# CH32H41X register map
Vendor: WCH Ltd.; File version: 1.2
Registers are 32-bit, read-write, reset 0x0 unless marked. A register's access mark holds for its fields unless they carry their own. Offsets are from the block's base; [hi:lo] are bit positions; lines under a group give offsets from that group; {n}, {i} and the like mark numbered series.

## I3C — Improved inter-integrated circuit
Base 0x40014400
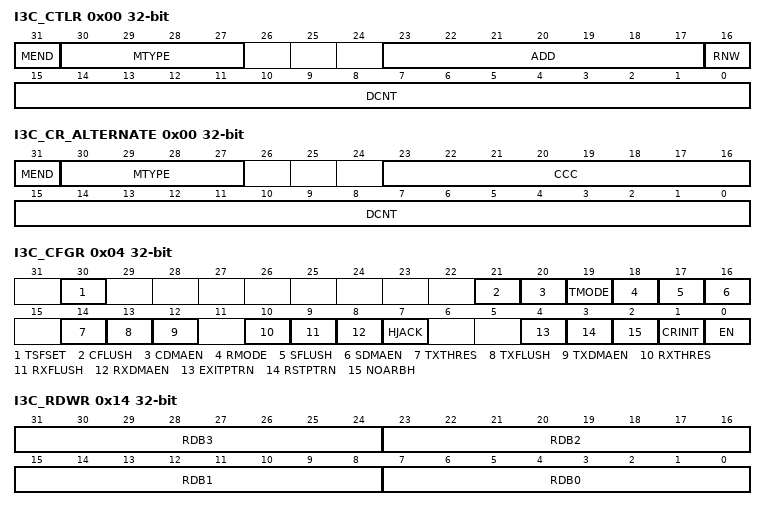
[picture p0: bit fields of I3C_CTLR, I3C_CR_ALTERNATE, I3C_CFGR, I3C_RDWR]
0x00 I3C_CTLR wo — I3C control register
  [31] MEND — message end type (when the I3C is acting as master)
  [30:27] MTYPE — message type
  [23:17] ADD — 7-bit I3C dynamic / I2C static slave address (when I3C is acting as master)
  [16] RNW — read / non-write message (when I3C is acting as master)
  [15:0] DCNT — count of data to transfer during a read or write message, in bytes (whatever I3C is acting as master/slave) Linear encoding up to 64 Kbytes -1
0x00 I3C_CR_ALTERNATE wo (alternate view of I3C_CTLR) — I3C message control register alternate
  [31] MEND — message end type (when I3C is acting as master)
  [30:27] MTYPE — message type (when I3C is acting as master)
  [23:16] CCC — 8-bit CCC code (when I3C is acting as master)
  [15:0] DCNT — count of data to transfer during a read or write message, in bytes (when I3C is acting as master) Linear encoding up to 64 Kbytes -1....
0x04 I3C_CFGR access per field — I3C configuration register
  [30] TSFSET wo — frame transfer set (a.k.a. software trigger) (when I3C is acting as master)
  [21] CFLUSH wo — C-FIFO flush (when I3C is acting as master)
  [20] CDMAEN rw — C-FIFO DMA request enable (when I3C is acting as master)
    0=DMA mode is disabled for C-FIFO; 1=DMA mode is enabled for C-FIFO
  [19] TMODE rw — transmit mode (when I3C is acting as master)
  [18] RMODE rw — S-FIFO enable / status receive mode (when I3C is acting as master)
  [17] SFLUSH wo — S-FIFO flush (when I3C is acting as master)
  [16] SDMAEN rw — S-FIFO DMA request enable (when I3C is acting as master)
  [14] TXTHRES rw — TX-FIFO threshold (whatever I3C is acting as master/slave)
  [13] TXFLUSH wo — TX-FIFO flush (whatever I3C is acting as master/slave)
  [12] TXDMAEN rw — TX-FIFO DMA request enable (whatever I3C is acting as master/slave)
  [10] RXTHRES rw — RX-FIFO threshold (whatever I3C is acting as master/slave)
  [9] RXFLUSH wo — RX-FIFO flush (whatever I3C is acting as master/slave)This bit can only be written.
  [8] RXDMAEN rw — RX-FIFO DMA request enable (whatever I3C is acting as master/slave)
  [7] HJACK rw — Hot Join request acknowledge (when I3C is acting as a master)
  [4] EXITPTRN rw — HDR Exit Pattern enable (when I3C is acting as a master)
  [3] RSTPTRN rw — HDR reset pattern enable (when I3C is acting as a master)
  [2] NOARBH rw — no arbitrable header after a START (when I3C is acting as a master)
  [1] CRINIT rw — initial master/slave role
  [0] EN rw — I3C enable (whatever I3C is acting as master/slave)
0x10 I3C_RDR ro — I3C receive data byte register
  [7:0] RDB0 — 8-bit received data on I3C bus.
0x14 I3C_RDWR ro — I3C receive data word register
  [31:24] RDB3 — 8-bit received data (latest byte on I3C bus).
  [23:16] RDB2 — 8-bit received data (next byte after RDB1 on I3C bus).
  [15:8] RDB1 — 8-bit received data (next byte after RDB0 on I3C bus).
  [7:0] RDB0 — 8-bit received data (earliest byte on I3C bus).
0x18 I3C_TDR wo — I3C transmit data byte register
  [7:0] TDB0 — 8-bit data to transmit on I3C bus.
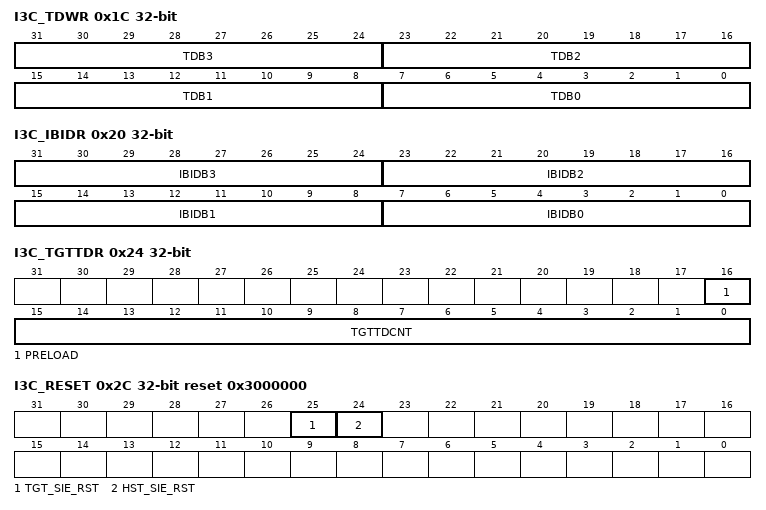
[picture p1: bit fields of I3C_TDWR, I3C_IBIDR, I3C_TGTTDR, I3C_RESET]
0x1C I3C_TDWR wo — I3C transmit data word register
  [31:24] TDB3 — 8-bit transmit data (latest byte on I3C bus).
  [23:16] TDB2 — 8-bit transmit data (next byte after TDB1[7:0] on I3C bus).
  [15:8] TDB1 — 8-bit transmit data (next byte after TDB0[7:0] on I3C bus).
  [7:0] TDB0 — 8-bit transmit data (earliest byte on I3C bus)
0x20 I3C_IBIDR — I3C IBI payload data register
  [31:24] IBIDB3 — 8-bit IBI payload data (latest byte on I3C bus).
  [23:16] IBIDB2 — 8-bit IBI payload data (next byte on I3C bus after IBIDB1[7:0]).
  [15:8] IBIDB1 — 8-bit IBI payload data (next byte on I3C bus after IBIDB0[7:0]).
  [7:0] IBIDB0 — 8-bit IBI payload data (earliest byte on I3C bus, i.e. MDB[7:0] mandatory data byte).
0x24 I3C_TGTTDR — I3C slave transmit configuration register
  [16] PRELOAD — preload of the TX-FIFO (when I3C is configured as slave)
  [15:0] TGTTDCNT — transmit data counter, in bytes (when I3C is configured as slave)
0x2C I3C_RESET reset 0x3000000
  [25] TGT_SIE_RST — Reset Register of the slave
  [24] HST_SIE_RST — Reset Register of the Master
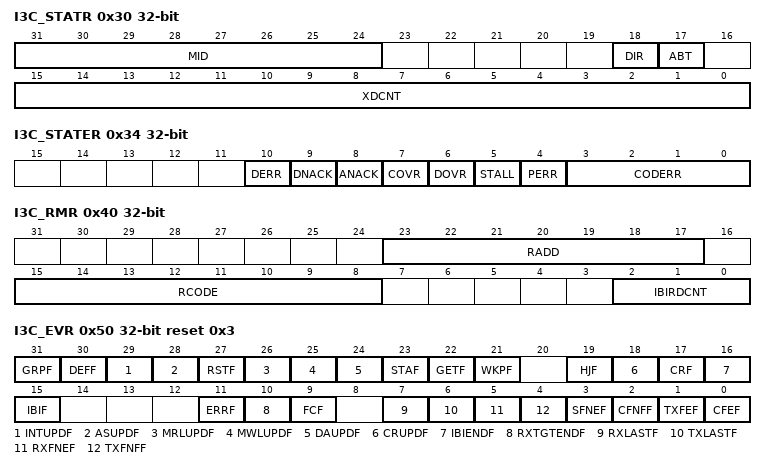
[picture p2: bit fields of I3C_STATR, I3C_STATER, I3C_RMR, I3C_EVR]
0x30 I3C_STATR ro — I3C status register
  [31:24] MID — message identifier/counter of a given frame (when the I3C is acting as master)
  [18] DIR — message direction(whatever I3C is acting as master/slave)
  [17] ABT — a private read message is completed/aborted prematurely by the slave (when the I3C is acting as master)
  [15:0] XDCNT — data counter
0x34 I3C_STATER ro — I3C status error register
  [10] DERR — data error (when the I3C is acting as master)
  [9] DNACK — data not acknowledged (when the I3C is acting as master)
  [8] ANACK — address not acknowledged (when the I3C is configured as master)
  [7] COVR — C-FIFO underrun or S-FIFO overrun (when the I3C is acting as master)
  [6] DOVR — RX-FIFO overrun or TX-FIFO underrun
  [5] STALL — SCL stall error (when the I3C is acting as slave)
  [4] PERR — protocol error
  [3:0] CODERR — protocol error code/type
0x40 I3C_RMR ro — I3C received message register
  [23:17] RADD — received slave address (when the I3C is configured as master)
  [15:8] RCODE — received CCC code (when the I3C is configured as slave)
  [2:0] IBIRDCNT — IBI received payload data count (when the I3C is configured as master)
0x50 I3C_EVR ro reset 0x3 — I3C event register
  [31] GRPF — group addressing flag (when the I3C is acting as slave)
  [30] DEFF — DEFTGTS flag (when the I3C is acting as slave)
  [29] INTUPDF — interrupt/master-role/hot-join update flag (when the I3C is acting as slave)
  [28] ASUPDF — activity state update flag (when the I3C is acting as slave)
  [27] RSTF — reset pattern flag (when the I3C is acting as slave)
  [26] MRLUPDF — maximum read length update flag (when the I3C is acting as slave)
  [25] MWLUPDF — maximum write length update flag (when the I3C is acting as slave)
  [24] DAUPDF — dynamic address update flag (when the I3C is acting as slave)
  [23] STAF — get status flag (when the I3C is acting as slave)
  [22] GETF — get flag (when the I3C is acting as slave)
  [21] WKPF — wakeup/missed start flag (when the I3C is acting as slave)
  [19] HJF — hot-join flag (when the I3C is acting as master)
  [18] CRUPDF — master-role update flag (when the I3C is acting as slave)
  [17] CRF — master-role request flag (when the I3C is acting as master)
  [16] IBIENDF — IBI end flag (when the I3C is acting as slave)
  [15] IBIF — IBI flag (when the I3C is acting as master)
  [11] ERRF — flag (whatever the I3C is acting as master/slave)
  [10] RXTGTENDF — slave-initiated read end flag (when the I3C is acting as master)
  [9] FCF — frame complete flag (whatever the I3C is acting as master/slave)
  [7] RXLASTF — last read data byte/word flag (whatever the I3C is acting as master/slave)
  [6] TXLASTF — last written data byte/word flag (whatever the I3C is acting as master/slave)
  [5] RXFNEF — RX-FIFO not empty flag (whatever the I3C is acting as master/slave)
  [4] TXFNFF — TX-FIFO not full flag (whatever the I3C is acting as master/slave)
  [3] SFNEF — S-FIFO not empty flag (when the I3C is acting as master)
  [2] CFNFF — C-FIFO not full flag (when the I3C is acting as master)
  [1] TXFEF — TX-FIFO empty flag (whatever the I3C is acting as master/slave)
  [0] CFEF — C-FIFO empty flag (whatever the I3C is acting as master/slave)
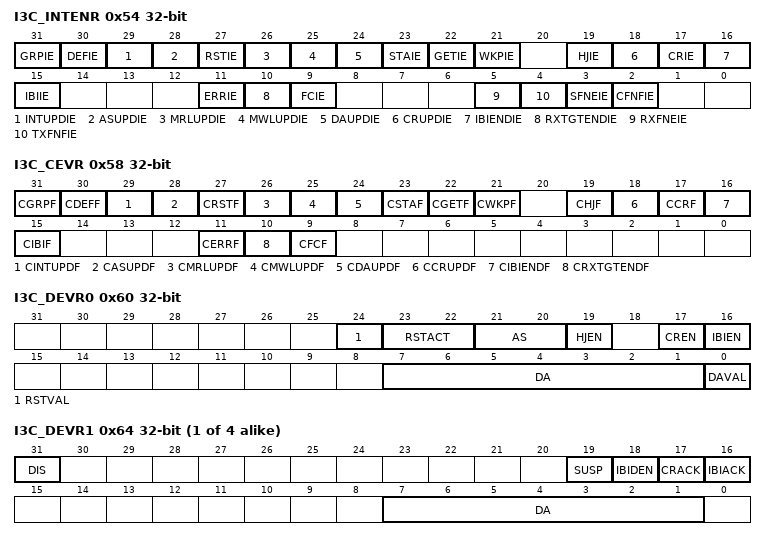
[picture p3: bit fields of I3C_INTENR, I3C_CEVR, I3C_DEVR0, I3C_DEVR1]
0x54 I3C_INTENR ro — I3C interrupt enable register
  [31] GRPIE — DEFGRPA CCC interrupt enable (when the I3C is acting as slave)
  [30] DEFIE — DEFTGTS CCC interrupt enable (when the I3C is acting as slave)
  [29] INTUPDIE — ENEC/DISEC CCC interrupt enable (when the I3C is acting as slave)
  [28] ASUPDIE — ENTASx CCC interrupt enable (when the I3C is acting as slave)
  [27] RSTIE — reset pattern interrupt enable (when the I3C is acting as slave)
  [26] MRLUPDIE — SETMRL CCC interrupt enable (when the I3C is acting as slave)
  [25] MWLUPDIE — SETMWL CCC interrupt enable (when the I3C is acting as slave)
  [24] DAUPDIE — ENTDAA/RSTDAA/SETNEWDA CCC interrupt enable (when the I3C is acting as slave)
  [23] STAIE — GETSTATUS CCC interrupt enable (when the I3C is acting as slave)
  [22] GETIE — GETxxx CCC interrupt enable (when the I3C is acting as slave)
  [21] WKPIE — wakeup interrupt enable (when the I3C is acting as slave)
  [19] HJIE — hot-join interrupt enable (when the I3C is acting as master)
  [18] CRUPDIE — master-role update interrupt enable (when the I3C is acting as slave)
  [17] CRIE — master-role request interrupt enable (when the I3C is acting as master)
  [16] IBIENDIE — IBI end interrupt enable (when the I3C is acting as slave)
  [15] IBIIE — IBI request interrupt enable (when the I3C is acting as master)
  [11] ERRIE — error interrupt enable (whatever the I3C is acting as master/slave)
  [10] RXTGTENDIE — slave-initiated read end interrupt enable (when the I3C is acting as master)
  [9] FCIE — frame complete interrupt enable (whatever the I3C is acting as master/slave)
  [5] RXFNEIE — RX-FIFO not empty interrupt enable (whatever the I3C is acting as master/slave)
  [4] TXFNFIE — TX-FIFO not full interrupt enable (whatever the I3C is acting as master/slave)
  [3] SFNEIE — S-FIFO not empty interrupt enable (whatever the I3C is acting as master/slave)
  [2] CFNFIE — C-FIFO not full interrupt enable (whatever the I3C is acting as master/slave)
0x58 I3C_CEVR wo — I3C clear event register
  [31] CGRPF — clear DEFGRPA CCC flag (when the I3C is acting as slave)
  [30] CDEFF — clear DEFTGTS CCC flag (when the I3C is acting as slave)
  [29] CINTUPDF — clear ENEC/DISEC CCC flag (when the I3C is acting as slave)
  [28] CASUPDF — clear ENTASx CCC flag (when the I3C is acting as slave)
  [27] CRSTF — clear reset pattern flag (when the I3C is acting as slave)
  [26] CMRLUPDF — clear SETMRL CCC flag (when the I3C is acting as slave)
  [25] CMWLUPDF — clear SETMWL CCC flag (when the I3C is acting as slave)
  [24] CDAUPDF — clear ENTDAA/RSTDAA/SETNEWDA CCC flag (when the I3C is acting as slave)
  [23] CSTAF — clear GETSTATUS CCC flag (when the I3C is acting as slave)
  [22] CGETF — clear GETxxx CCC flag (when the I3C is acting as slave)
  [21] CWKPF — clear wakeup flag (when the I3C is acting as slave)
  [19] CHJF — clear hot-join flag (when the I3C is acting as master)
  [18] CCRUPDF — clear master-role update flag (when the I3C is acting as slave)
  [17] CCRF — clear master-role request flag (when the I3C is acting as master)
  [16] CIBIENDF — clear IBI end flag (when the I3C is acting as slave)
  [15] CIBIF — clear IBI request flag (when the I3C is acting as master)
  [11] CERRF — clear error flag (whatever the I3C is acting as master/slave)
  [10] CRXTGTENDF — clear slave-initiated read end flag (when the I3C is acting as master)
  [9] CFCF — clear frame complete flag (whatever the I3C is acting as master/slave)
0x60 I3C_DEVR0 access per field — I3C own device characteristics register
  [24] RSTVAL ro — reset action is valid (when the I3C is acting as slave)
  [23:22] RSTACT ro — reset action/level on received reset pattern (when the I3C is acting as slave)
  [21:20] AS ro — activity state (when the I3C is acting as slave)
  [19] HJEN rw — hot-join request enable (when the I3C is acting as slave)
  [17] CREN rw — master-role request enable (when the I3C is acting as slave)
  [16] IBIEN rw — IBI request enable (when the I3C is acting as slave)
  [7:1] DA rw — 7-bit dynamic address
  [0] DAVAL rw — dynamic address is valid (when the I3C is acting as slave)
{0x60+4i} I3C_DEVR{i} access per field (i=1..4) — I3C device {i} characteristics register
  [31] DIS ro — DA[6:0] write disabled (when the I3C is acting as master)
  [19] SUSP rw — suspend/stop I3C transfer on received IBI (when the I3C is acting as master)
  [18] IBIDEN rw — IBI data enable (when the I3C is acting as master)
  [17] CRACK rw — master-role request acknowledge (when the I3C is acting as master)
  [16] IBIACK rw — IBI request acknowledge (when the I3C is acting as master)
  [7:1] DA rw — assigned I3C dynamic address to slave x (when the I3C is acting as master)
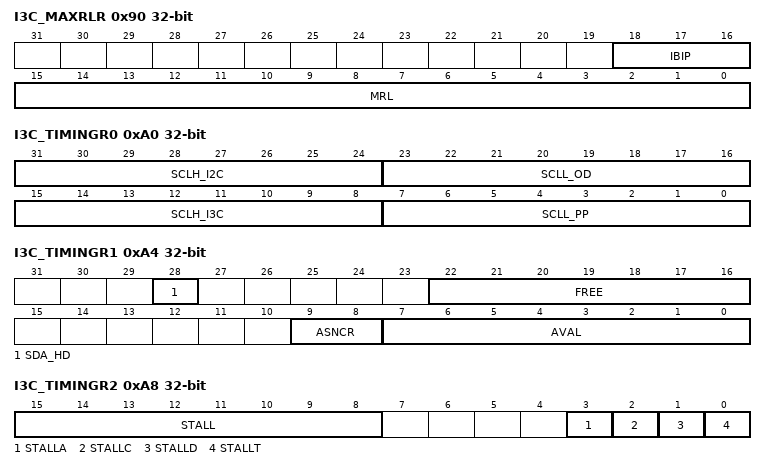
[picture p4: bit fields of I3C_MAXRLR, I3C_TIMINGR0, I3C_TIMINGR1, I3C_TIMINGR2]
0x90 I3C_MAXRLR — I3C maximum read length register
  [18:16] IBIP — IBI payload data size, in bytes (when I3C is acting as slave)
  [15:0] MRL — maximum data read length (when I3C is acting as slave)
0x94 I3C_MAXWLR — I3C maximum write length register
  [15:0] MWL — maximum data write length (when I3C is acting as slave)
0xA0 I3C_TIMINGR0 — I3C timing register 0
  [31:24] SCLH_I2C — SCL high duration, used for legacy I2C commands, in number of kernel clocks cycles
  [23:16] SCLL_OD — SCL low duration in open-drain phases, used for legacy I2C commands and for I3C open-drain phases (address header phase following a START, not a Repeated START), in number of kernel clocks cycles
  [15:8] SCLH_I3C — SCL high duration, used for I3C messages (both in push-pull and open-drain phases), in number of kernel clocks cycles
  [7:0] SCLL_PP — SCL low duration in I3C push-pull phases, in number of kernel clocks cycles
0xA4 I3C_TIMINGR1 — I3C timing register 1
  [28] SDA_HD — SDA hold time (when the I3C is acting as master), in number of kernel clocks cycles (refer to MIPI timing SDA hold time in push-pull tHD_PP):
  [22:16] FREE — number of kernel clocks cycles that is used to set some MIPI timings like bus free condition time (when the I3C is acting as master)
  [9:8] ASNCR — activity state of the new master (when I3C is acting as active- master)
  [7:0] AVAL — number of kernel clock cycles, that is used whatever I3C is acting as controller or slave, to set the following MIPI I3C timings, like bus available condition time: When the I3C is acting as slave
0xA8 I3C_TIMINGR2 — I3C timing register 2
  [15:8] STALL — master clock stall time, in number of kernel clock cycles
  [3] STALLA — master clock stall enable on ACK phase
  [2] STALLC — master clock stall on PAR phase of CCC enable
  [1] STALLD — master clock stall on PAR phase of Data enable
  [0] STALLT — master clock stall on T-bit phase of Data enable
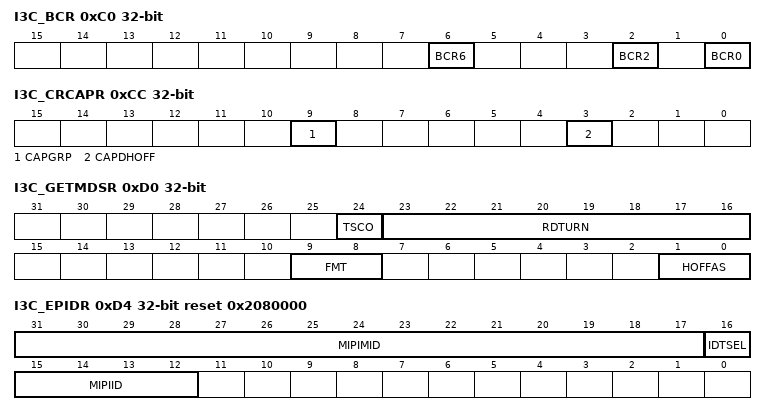
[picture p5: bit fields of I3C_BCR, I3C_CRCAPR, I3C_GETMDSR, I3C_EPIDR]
0xC0 I3C_BCR — I3C bus characteristics register
  [6] BCR6 — master capable
  [2] BCR2 — in-band interrupt (IBI) payload
  [0] BCR0 — max data speed limitation
0xC4 I3C_DCR — I3C device characteristics register
  [7:0] DCR — device characteristics ID
0xC8 I3C_GETCAPR — I3C get capability register
  [14] CAPPEND — IBI MDB support for pending read notification
0xCC I3C_CRCAPR — I3C master-role capability register
  [9] CAPGRP — group management support (when acting as master)
  [3] CAPDHOFF — delayed master-role hand-off
0xD0 I3C_GETMDSR — I3C get capability register
  [24] TSCO — clock-to-data turnaround time (tSCO)
  [23:16] RDTURN — programmed byte of the 3-byte MaxRdTurn (maximum read turnaround byte)
  [9:8] FMT — GETMXDS CCC format
  [1:0] HOFFAS — master hand-off activity state
0xD4 I3C_EPIDR access per field reset 0x2080000 — I3C extended provisioned ID register
  [31:17] MIPIMID ro — 15-bit MIPI manufacturer ID
  [16] IDTSEL ro — provisioned ID type selector
  [15:12] MIPIID rw — 4-bit MIPI Instance ID
